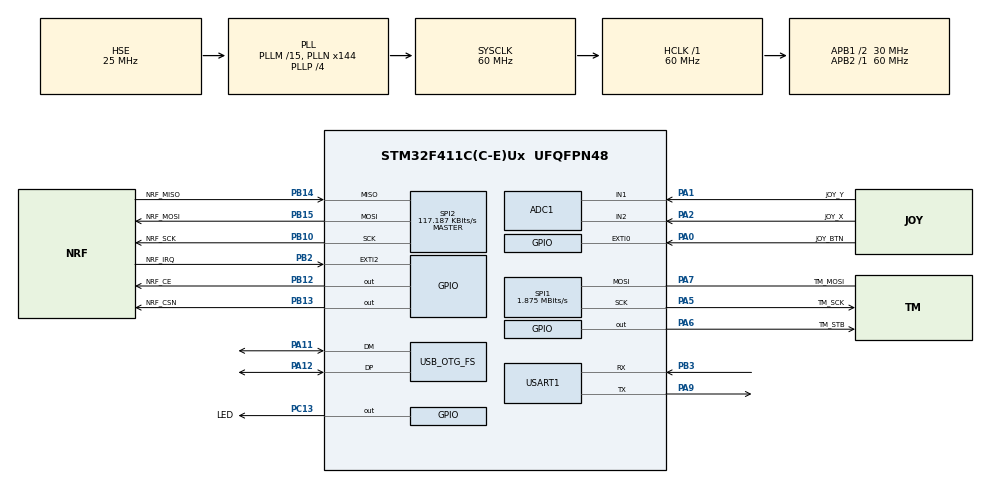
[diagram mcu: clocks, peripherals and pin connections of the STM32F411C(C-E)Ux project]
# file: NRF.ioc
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ADC1.Channel-5\#ChannelRegularConversion=ADC_CHANNEL_1
ADC1.Channel-6\#ChannelRegularConversion=ADC_CHANNEL_2
ADC1.ContinuousConvMode=ENABLE
ADC1.DMAContinuousRequests=ENABLE
ADC1.EOCSelection=ADC_EOC_SEQ_CONV
ADC1.ExternalTrigConv=ADC_EXTERNALTRIGCONV_T2_TRGO
ADC1.ExternalTrigConvEdge=ADC_EXTERNALTRIGCONVEDGE_RISINGFALLING
ADC1.NbrOfConversion=2
ADC1.NbrOfConversionFlag=1
ADC1.Rank-5\#ChannelRegularConversion=1
ADC1.Rank-6\#ChannelRegularConversion=2
ADC1.SamplingTime-5\#ChannelRegularConversion=ADC_SAMPLETIME_144CYCLES
ADC1.SamplingTime-6\#ChannelRegularConversion=ADC_SAMPLETIME_144CYCLES
ADC1.master=1
Dma.ADC1.0.Direction=DMA_PERIPH_TO_MEMORY
Dma.ADC1.0.FIFOMode=DMA_FIFOMODE_DISABLE
Dma.ADC1.0.Instance=DMA2_Stream0
Dma.ADC1.0.MemDataAlignment=DMA_MDATAALIGN_HALFWORD
Dma.ADC1.0.MemInc=DMA_MINC_ENABLE
Dma.ADC1.0.Mode=DMA_CIRCULAR
Dma.ADC1.0.PeriphDataAlignment=DMA_PDATAALIGN_HALFWORD
Dma.ADC1.0.PeriphInc=DMA_PINC_DISABLE
Dma.ADC1.0.Priority=DMA_PRIORITY_LOW
Dma.Request0=ADC1
Mcu.Family=STM32F4
Mcu.Name=STM32F411C(C-E)Ux
Mcu.Package=UFQFPN48
NVIC.ADC_IRQn=true\:0\:0\:false\:false\:true\:true\:true\:true
NVIC.DMA2_Stream0_IRQn=true\:0\:0\:false\:false\:true\:false\:true\:true
NVIC.EXTI0_IRQn=true\:0\:0\:false\:false\:true\:true\:true\:true
NVIC.EXTI2_IRQn=true\:0\:0\:false\:false\:true\:true\:true\:true
NVIC.OTG_FS_IRQn=true\:0\:0\:false\:false\:true\:false\:true\:true
NVIC.PriorityGroup=NVIC_PRIORITYGROUP_4
NVIC.SPI2_IRQn=true\:0\:0\:false\:false\:true\:true\:true\:true
NVIC.TIM2_IRQn=true\:0\:0\:false\:false\:true\:true\:true\:true
NVIC.USART1_IRQn=true\:0\:0\:false\:false\:true\:true\:true\:true
PA0-WKUP.GPIO_Label=JOY_BTN
PA0-WKUP.GPIO_ModeDefaultEXTI=GPIO_MODE_IT_RISING_FALLING
PA0-WKUP.GPIO_PuPd=GPIO_PULLUP
PA0-WKUP.Signal=GPXTI0
PA1.GPIO_Label=JOY_Y
PA1.Signal=ADCx_IN1
PA11.Mode=Device_Only
PA11.Signal=USB_OTG_FS_DM
PA12.Mode=Device_Only
PA12.Signal=USB_OTG_FS_DP
PA13.Mode=Serial_Wire
PA13.Signal=SYS_JTMS-SWDIO
PA14.Mode=Serial_Wire
PA14.Signal=SYS_JTCK-SWCLK
PA2.GPIO_Label=JOY_X
PA2.Signal=ADCx_IN2
PA5.GPIO_Label=TM_SCK
PA5.GPIO_Speed=GPIO_SPEED_FREQ_HIGH
PA5.Mode=Simplex_Bidirectional_Master
PA5.Signal=SPI1_SCK
PA6.GPIO_Label=TM_STB
PA6.Signal=GPIO_Output
PA7.GPIO_Label=TM_MOSI
PA7.GPIO_Speed=GPIO_SPEED_FREQ_HIGH
PA7.Mode=Simplex_Bidirectional_Master
PA7.Signal=SPI1_MOSI
PA9.GPIO_Speed=GPIO_SPEED_FREQ_HIGH
PA9.Mode=Asynchronous
PA9.Signal=USART1_TX
PB10.GPIO_Label=NRF_SCK
PB10.GPIO_Speed=GPIO_SPEED_FREQ_VERY_HIGH
PB10.Mode=Full_Duplex_Master
PB10.Signal=SPI2_SCK
PB12.GPIO_Label=NRF_CE
PB12.Signal=GPIO_Output
PB13.GPIO_Label=NRF_CSN
PB13.Signal=GPIO_Output
PB14.GPIO_Label=NRF_MISO
PB14.GPIO_Speed=GPIO_SPEED_FREQ_VERY_HIGH
PB14.Mode=Full_Duplex_Master
PB14.Signal=SPI2_MISO
PB15.GPIO_Label=NRF_MOSI
PB15.GPIO_Speed=GPIO_SPEED_FREQ_VERY_HIGH
PB15.Mode=Full_Duplex_Master
PB15.Signal=SPI2_MOSI
PB2.GPIO_Label=NRF_IRQ
PB2.GPIO_ModeDefaultEXTI=GPIO_MODE_IT_FALLING
PB2.GPIO_PuPd=GPIO_PULLUP
PB2.Signal=GPXTI2
PB3.GPIO_Speed=GPIO_SPEED_FREQ_HIGH
PB3.Mode=Asynchronous
PB3.Signal=USART1_RX
PC13-ANTI_TAMP.GPIO_Label=LED
PC13-ANTI_TAMP.Signal=GPIO_Output
PH0\ -\ OSC_IN.Mode=HSE-External-Oscillator
PH0\ -\ OSC_IN.Signal=RCC_OSC_IN
PH1\ -\ OSC_OUT.Mode=HSE-External-Oscillator
PH1\ -\ OSC_OUT.Signal=RCC_OSC_OUT
ProjectManager.HeapSize=0x200
ProjectManager.StackSize=0x400
ProjectManager.TargetToolchain=STM32CubeIDE
RCC.48MHZClocksFreq_Value=48000000
RCC.AHBFreq_Value=60000000
RCC.APB1CLKDivider=RCC_HCLK_DIV2
RCC.APB1Freq_Value=30000000
RCC.APB1TimFreq_Value=60000000
RCC.APB2Freq_Value=60000000
RCC.APB2TimFreq_Value=60000000
RCC.CortexFreq_Value=60000000
RCC.HCLKFreq_Value=60000000
RCC.HSE_VALUE=25000000
RCC.HSI_VALUE=16000000
RCC.LSE_VALUE=32768
RCC.PLLM=15
RCC.PLLN=144
RCC.PLLP=RCC_PLLP_DIV4
RCC.PLLQ=5
RCC.SYSCLKFreq_VALUE=60000000
RCC.SYSCLKSource=RCC_SYSCLKSOURCE_PLLCLK
RCC.VCOOutputFreq_Value=240000000
SH.ADCx_IN1.0=ADC1_IN1,IN1
SH.ADCx_IN2.0=ADC1_IN2,IN2
SPI1.BaudRatePrescaler=SPI_BAUDRATEPRESCALER_32
SPI1.CLKPhase=SPI_PHASE_2EDGE
SPI1.CLKPolarity=SPI_POLARITY_HIGH
SPI1.CalculateBaudRate=1.875 MBits/s
SPI1.Direction=SPI_DIRECTION_1LINE
SPI1.FirstBit=SPI_FIRSTBIT_LSB
SPI1.Mode=SPI_MODE_MASTER
SPI1.VirtualType=VM_MASTER
SPI2.BaudRatePrescaler=SPI_BAUDRATEPRESCALER_256
SPI2.CRCCalculation=SPI_CRCCALCULATION_DISABLE
SPI2.CalculateBaudRate=117.187 KBits/s
SPI2.Direction=SPI_DIRECTION_2LINES
SPI2.Mode=SPI_MODE_MASTER
SPI2.VirtualType=VM_MASTER
TIM2.Period=4000-1
TIM2.Prescaler=60000-1
TIM2.TIM_MasterOutputTrigger=TIM_TRGO_UPDATE
USART1.VirtualMode=VM_ASYNC
USB_DEVICE.CLASS_NAME_FS=CDC
USB_DEVICE.VirtualMode=Cdc
USB_DEVICE.VirtualModeFS=Cdc_FS
USB_OTG_FS.VirtualMode=Device_Only
VP_TIM2_VS_ClockSourceINT.Mode=Internal
VP_TIM2_VS_ClockSourceITR.Mode=TriggerSource_ITR0
VP_USB_DEVICE_VS_USB_DEVICE_CDC_FS.Mode=CDC_FS
board=custom

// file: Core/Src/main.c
/* USER CODE BEGIN Header */
/**
  ******************************************************************************
  * @file           : main.c
  * @brief          : Main program body
  ******************************************************************************
  * @attention
  *
  * Copyright (c) 2024 STMicroelectronics.
  * All rights reserved.
  *
  * This software is licensed under terms that can be found in the LICENSE file
  * in the root directory of this software component.
  * If no LICENSE file comes with this software, it is provided AS-IS.
  *
  ******************************************************************************
  */
/* USER CODE END Header */
#include "main.h"
#include "adc.h"
#include "dma.h"
#include "spi.h"
#include "tim.h"
#include "usart.h"
#include "usb_device.h"
#include "gpio.h"

/* USER CODE BEGIN Includes */
#include "EventLoop.h"

/* USER CODE END Includes */

void SystemClock_Config(void);

int main(void)
{

  /* MCU Configuration--------------------------------------------------------*/

  /* Reset of all peripherals, Initializes the Flash interface and the Systick. */
  HAL_Init();

  /* Configure the system clock */
  SystemClock_Config();

  /* Initialize all configured peripherals */
  MX_GPIO_Init();
  MX_DMA_Init();
  MX_SPI2_Init();
  MX_SPI1_Init();
  MX_ADC1_Init();
  MX_USART1_UART_Init();
  MX_USB_DEVICE_Init();
  MX_TIM2_Init();

  /* Infinite loop */
  /* USER CODE BEGIN WHILE */

  EventLoopC();

  while (1)
  {
    /* USER CODE END WHILE */

    /* USER CODE BEGIN 3 */
	  //nRF24_ReadReg();
//	  nRF24_Check();
//	  char status = nRF24_GetStatus();

  	// Prepare data packet
//  	for (i = 0; i < payload_length; i++) {
//  		nRF24_payload[i] = j++;
//  		if (j > 0x000000FF) j = 0;
//  	}

  }
  /* USER CODE END 3 */
}

void SystemClock_Config(void)
{
  RCC_OscInitTypeDef RCC_OscInitStruct = {0};
  RCC_ClkInitTypeDef RCC_ClkInitStruct = {0};

  /** Configure the main internal regulator output voltage
  */
  __HAL_RCC_PWR_CLK_ENABLE();
  __HAL_PWR_VOLTAGESCALING_CONFIG(PWR_REGULATOR_VOLTAGE_SCALE1);

  /** Initializes the RCC Oscillators according to the specified parameters
  * in the RCC_OscInitTypeDef structure.
  */
  RCC_OscInitStruct.OscillatorType = RCC_OSCILLATORTYPE_HSE;
  RCC_OscInitStruct.HSEState = RCC_HSE_ON;
  RCC_OscInitStruct.PLL.PLLState = RCC_PLL_ON;
  RCC_OscInitStruct.PLL.PLLSource = RCC_PLLSOURCE_HSE;
  RCC_OscInitStruct.PLL.PLLM = 15;
  RCC_OscInitStruct.PLL.PLLN = 144;
  RCC_OscInitStruct.PLL.PLLP = RCC_PLLP_DIV4;
  RCC_OscInitStruct.PLL.PLLQ = 5;
  if (HAL_RCC_OscConfig(&RCC_OscInitStruct) != HAL_OK)
  {
    Error_Handler();
  }

  /** Initializes the CPU, AHB and APB buses clocks
  */
  RCC_ClkInitStruct.ClockType = RCC_CLOCKTYPE_HCLK|RCC_CLOCKTYPE_SYSCLK
                              |RCC_CLOCKTYPE_PCLK1|RCC_CLOCKTYPE_PCLK2;
  RCC_ClkInitStruct.SYSCLKSource = RCC_SYSCLKSOURCE_PLLCLK;
  RCC_ClkInitStruct.AHBCLKDivider = RCC_SYSCLK_DIV1;
  RCC_ClkInitStruct.APB1CLKDivider = RCC_HCLK_DIV2;
  RCC_ClkInitStruct.APB2CLKDivider = RCC_HCLK_DIV1;

  if (HAL_RCC_ClockConfig(&RCC_ClkInitStruct, FLASH_LATENCY_1) != HAL_OK)
  {
    Error_Handler();
  }
}

void Error_Handler(void)
{
  __disable_irq();
  while (1)
  {
  }
}
